VERSION ""

NS_ :

BS_:
BU_: Charger
BO_ 1118 Charger_Port_Door_State: 8 Charger
   SG_ Door : 43|1@0+ (1,0) [0|1] "" Vector__XXX

BO_ 1120 Charger_Voltage_Level: 8 Charger
   SG_ Voltage : 15|12@0+ (0.1,0) [0|120] "V" Vector__XXX

BO_ 1122 Charger_Current_State: 8 Charger
   SG_ Current : 31|7@0+ (0.5,0) [0|50] "A" Vector__XXX

BO_ 1124 Charger_Temperature_State: 8 Charger
   SG_ Temperature : 24|8@0+ (0.1,0) [0|100] "°C" Vector__XXX

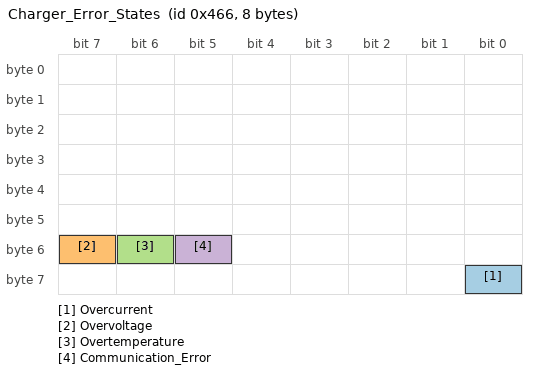
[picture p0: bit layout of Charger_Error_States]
BO_ 1126 Charger_Error_States: 8 Charger
   SG_ Overcurrent : 56|1@0+ (1,0) [0|0] "" Vector__XXX
   SG_ Overvoltage : 55|1@0+ (1,0) [0|0] "" Vector__XXX
   SG_ Overtemperature : 54|1@0+ (1,0) [0|0] "" Vector__XXX
   SG_ Communication_Error : 53|1@0+ (1,0) [0|0] "" Vector__XXX

BO_ 1130 Charger_Operational_Status: 8 Charger
   SG_ Charging : 47|1@0+ (1,0) [0|1] "" Vector__XXX
   SG_ Fault : 46|1@0+ (1,0) [0|1] "" Vector__XXX

BA_DEF_ BO_ "GenMsgBackgroundColor" STRING ;
BA_DEF_ BO_ "GenMsgForegroundColor" STRING ;
BA_DEF_ BO_ "filterlabeling" INT 0 0;
BA_DEF_DEF_ "GenMsgBackgroundColor" "#ffffff";
BA_DEF_DEF_ "GenMsgForegroundColor" "#000000";
BA_DEF_DEF_ "filterlabeling" 1;

VAL_ 1118 Door 0 "Closed" 1 "Open";
VAL_ 1120 Voltage 0 "Low" 1 "Medium" 2 "High";
VAL_ 1122 Current 0 "Idle" 1 "Charging" 2 "Discharging";
VAL_ 1124 Temperature 0 "Normal" 1 "High" 2 "Low";
VAL_ 1126 Error 0 "No Error" 1 "Overcurrent" 2 "Overvoltage" 3 "Overtemperature" 4 "Communication Error";
VAL_ 1130 OperationalStatus 0 "Idle" 1 "Charging" 2 "Fault";
